# PIC32CX0525SG12144 register map
Vendor: Microchip Technology; Series: 0525SG12; File version: 0
CPU: CM4 r1p0, little endian, no MPU, no FPU, 3 interrupt priority bits, 172 interrupts
Registers are 32-bit, read-write, reset 0x0 unless marked. A register's access mark holds for its fields unless they carry their own. Offsets are from the block's base; [hi:lo] are bit positions; {n}, {i} and the like mark numbered series.

## VBAT_RAM — The VBAT RAM is operational while the main power rail is operational, and will retain its values powered by battery power while the main rail is unpowered.
Base 0x4000A800
{0x0+4i} MEM[{i}] (i=0..15) — 32-bits of VBAT powered RAM.

## ESPI_SCRATCH — 32 Byte ESPI Test Register
Base 0x400FBC00
{0x0+4i} SCRATCH{i} (i=0..7)
  [31:0] SCR{i} — This field has no functionality other than storage. This register is aliased to ESPI Config Scratch Register.

## SAFCOMM — This region contains one register “SAF Communication Mode” that may (and should) be set for optimal SAFS operation
Base 0x40071000
0x2B8 COMM_MODE — This register contains one bit PREFETCH_EN that should be set to '1' during initialization, to enable Prefetch Mode operation in SAFS Mode.
  [0] PREFETCH_EN — 1= Allow Prefetching from Flash devices, and use the bits CS0_PREFETCH_OPT_EN and CS1_PREFETCH_OPT_EN to select any additional optimization. 0= Do not perform Prefetches from Flash devices

## SGPIO0 — This is Serial General Purpous Input Output block
Base 0x4000A000; register names take the prefix SGPIO_
Same registers: SGPIO1 0x4000A100, SGPIO2 0x4000A200, SGPIO3 0x4000A300
0x00 CFG 8-bit ro reset 0x4 — SGPIO Configuration Register.
  [3:0] DRIVCNT — This field indicates the number of drives supported in each packet by the SGPIO_TARGET_SPB block. The number of bits shifted in and out is three times the value of this field, since there are three LEDs per drive. This field is hard-coded to 04h.
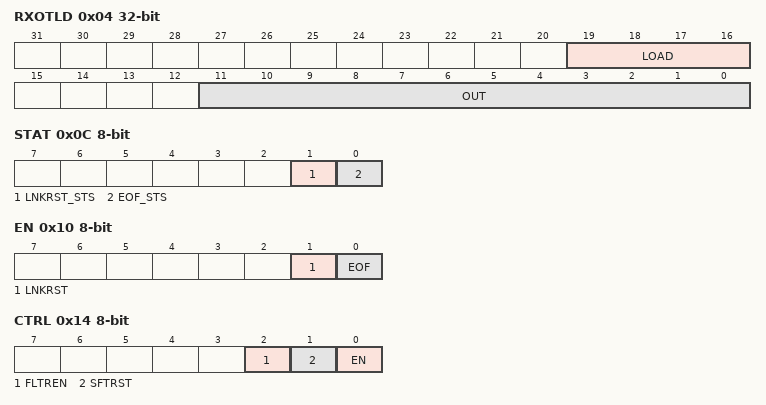
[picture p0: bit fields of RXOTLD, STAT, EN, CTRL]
0x04 RXOTLD ro — This register contains the values received during the last SGPIO transaction.
  [19:16] LOAD — This field contains the values shifted in from the SGPIO_LD pin. This field clears to zero when a link-reset is detected.
  [11:0] OUT — This field contains the values shifted in from the SGPIO_OUT pin. This field clears to zero when a link-reset is detected.
0x08 TXIN — This register contains the values to be transmitted during the next SGPIO transaction.
  [11:0] IN
0x0C STAT 8-bit — This register contains the SPIO status.
  [1] LNKRST_STS — This field is set by the hardware whenever the SGPIO pins have been detected high for atleast 64ms. This field is cleared by F/W writing a 1. This is R/WC
  [0] EOF_STS — This field is set by the hardware whenever a SGPIO frame has finished shifting on the bus. This field is cleared by F/W writing a 1. This is R/WC
0x10 EN 8-bit — This is register SPIO Enable Register.
  [1] LNKRST — When this bit is set and sts_link_reset is asserted by the h/w, an interrupt is thrown to the processor.
  [0] EOF — When this bit is set and sts_eof is asserted by the h/w, an interrupt is thrown to the processor.
0x14 CTRL 8-bit — This is the SPIO Control Register.
  [2] FLTREN — When this bit is set to one, analog filters will be used to remove up to 50ns glitches on SGPIO_CLK, SGPIO_DOUT, and SGPIO_LD.
  [1] SFTRST — When this bit is set to one, the SGPIO_TARGET_SPB block will reset. This bit is self clearing. This field is auto cleared by hardware.
  [0] EN — When this bit is set to one, the SGPIO_TARGET_SPB block will be enabled.

## OTP — OTP Programming registers.
Base 0x40082000
0x44 WRLOCK — This is the Write Lock Register.
  [31:0] WL — When any of the bits are set, the corresponding 32byte range in the OTP is not writable.
0x48 RDLOCK — This is the Read Lock Register.
  [31:0] RDLOCK — When any of the bits are set, the corresponding 32byte range in the OTP is not readable.

## NVIC — Nested Vectored Interrupt Controller
Base 0xE000E100
{0x0+4i} ISER[{i}] (i=0..0) — Interrupt Set Enable Register
  [31:0] SETENA — Interrupt set enable bits
{0x80+4i} ICER[{i}] (i=0..0) — Interrupt Clear Enable Register
  [31:0] CLRENA — Interrupt clear-enable bits
{0x100+4i} ISPR[{i}] (i=0..0) — Interrupt Set Pending Register
  [31:0] SETPEND — Interrupt set-pending bits
{0x180+4i} ICPR[{i}] (i=0..0) — Interrupt Clear Pending Register
  [31:0] CLRPEND — Interrupt clear-pending bits
{0x200+4i} IABR[{i}] (i=0..0) — Interrupt Active Bit Register
  [31:0] ACTIVE — Interrupt active bits
{0x300+i} IP[{i}] (i=0..7) 8-bit — Interrupt Priority Register n
  [2:0] PRI0 — Priority of interrupt n
0xE00 STIR wo — Software Trigger Interrupt Register
  [8:0] INTID — Interrupt ID to trigger

## SysTick — System timer
Base 0xE000E010
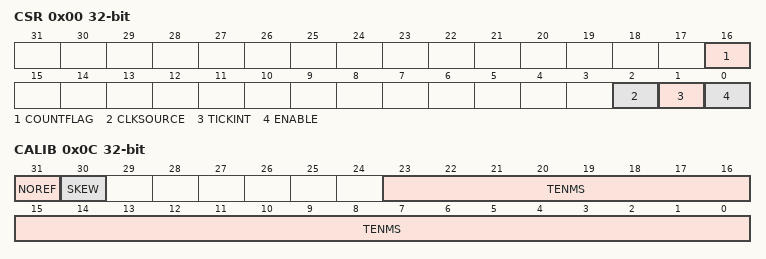
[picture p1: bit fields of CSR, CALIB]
0x00 CSR — SysTick Control and Status Register
  [16] COUNTFLAG — Timer counted to 0 since last read of register
  [2] CLKSOURCE — Clock Source 0=external, 1=processor
    0=External clock; 1=Processor clock
  [1] TICKINT — SysTick Exception Request Enable
    0=Counting down to 0 does not assert the SysTick exception request; 1=Counting down to 0 asserts the SysTick exception request
  [0] ENABLE — SysTick Counter Enable
    0=Counter disabled; 1=Counter enabled
0x04 RVR — SysTick Reload Value Register
  [23:0] RELOAD — Value to load into the SysTick Current Value Register when the counter reaches 0
0x08 CVR — SysTick Current Value Register
  [23:0] CURRENT — Current value at the time the register is accessed
0x0C CALIB ro — SysTick Calibration Value Register
  [31] NOREF — No Separate Reference Clock
    0=The reference clock is provided; 1=The reference clock is not provided
  [30] SKEW — TENMS is rounded from non-integer ratio
    0=10ms calibration value is exact; 1=10ms calibration value is inexact, because of the clock frequency
  [23:0] TENMS — Reload value to use for 10ms timing
